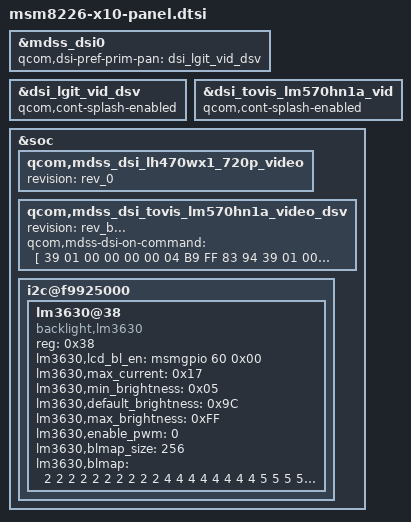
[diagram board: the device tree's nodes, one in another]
/* Copyright (c) 2013, Code Aurora Forum. All rights reserved.
 *
 * This program is free software; you can redistribute it and/or modify
 * it under the terms of the GNU General Public License version 2 and
 * only version 2 as published by the Free Software Foundation.
 *
 * This program is distributed in the hope that it will be useful,
 * but WITHOUT ANY WARRANTY; without even the implied warranty of
 * MERCHANTABILITY or FITNESS FOR A PARTICULAR PURPOSE.  See the
 * GNU General Public License for more details.
 */

&mdss_dsi0 {
	qcom,dsi-pref-prim-pan = <&dsi_lgit_vid_dsv>;
};

&dsi_lgit_vid_dsv {
	qcom,cont-splash-enabled;
};
&dsi_tovis_lm570hn1a_vid {
	qcom,cont-splash-enabled;
};

&soc {
	qcom,mdss_dsi_lh470wx1_720p_video {
		status = "ok";
		revision = "rev_0";
	};
	qcom,mdss_dsi_tovis_lm570hn1a_video_dsv {
		status = "ok";
		revision = "rev_a";
		qcom,mdss-dsi-on-command = [
		39 01 00 00 00 00 04	/*Set EXTC*/
		B9 FF 83 94

		39 01 00 00 00 00 03   /*Set MIPI*/
		BA 33 83

		39 01 00 00 00 00 10  /*Set Power*/
		B1 6C 12/*4 Power Mode*/ 12
		34 04 11 F1
		80 FF 54 23
		80 C0 D2 58

		39 01 00 00 00 00 0C /*Set Display*/
		B2 00 64 0E
		0D 32 1C 08
		08 1C 4D 00

		39 01 00 00 00 00 0D /*Set CYC*/
		B4 00 FF 51
		5A 59 5A 03
		5A 01 70 01
		70

		/*Set VCOM*/
		39 01 00 00 00 00 04
		B6 73 73 E0

		/*Set Gamma*/
		39 01 00 00 00 00 2B
		E0 00 29 2C 2F 31 3F 2A 3F 06 0A 0C 17 0E 11 14 12 14 08 12 12
		16 00 29 2B 2D 32 3F 2A 3F 08 0B 0C 17 0D 10 13 12 12 06 11 13 18

		39 01 00 00 00 00 26 /*Set GIP*/
		D3 00 07 00
		40 07 10 00
		08 10 08 00
		08 54 15 0E
		05 0E 02 15
		06 05 06 47
		44 0A 0A 4B
		10 07 07 08
		00 00 00 0A
		00 01

		39 01 00 00 00 00 2D /*GIP Forward*/
		D5 1A 1A 1B
		1B 00 01 02
		03 04 05 06
		07 08 09 0A
		0B 24 25 18
		18 26 27 18
		18 18 18 18
		18 18 18 18
		18 18 18 18
		18 18 18 20
		21 18 18 18
		18

		39 01 00 00 00 00 2D /*GIP Backward*/
		D6 1A 1A 1B
		1B 0B 0A 09
		08 07 06 05
		04 03 02 01
		00 21 20 58
		58 27 26 18
		18 18 18 18
		18 18 18 18
		18 18 18 18
		18 18 18 25
		24 18 18 18
		18

		39 01 00 00 00 00 02  /*Set Panel*/
		CC 09

		39 01 00 00 00 00 05  /*Set TCON*/
		C7 00 C0 00
		C0

		/*05 01 00 00 78 00 01	  11  */  /*Sleep out*/

		/* set_chemode */
		39 01 00 00 00 00 03
		E4 01 00

		/* set_che */
		39 01 00 00 00 00 13
		E5 00 0C 1F
		07 04 00 08
		20 00 10 00
		00 08 06 04
		00 80 0E

		/* set_chesel */
		39 01 00 00 00 00 12
		E6 40 00 00
		05 05 10 10
		10 04 04 08
		10 10 10 10
		1010

		/*05 01 00 00 0A 00 01	  29 */  /*Display on*/


		/* CABC */
		/*
		15 01 00 00 00 00 02 51 FF
		15 01 00 00 00 00 02 53 24
		15 01 00 00 05 00 02 55 01
		39 01 00 00 00 00 0A
		C9 0F 00 1E 02 00 80 00 01 3E
		*/
		/* CABC */
		/*
		05 01 00 00 96 00 02 11 00
		39 01 00 00 00 00 14
		B1 00 00 07 E3 91 10 11 6F 0C 1D 25 1E 1E 41 01 58 F7 00 00
		05 01 00 00 0a 00 01 29 */
		];
	};

	qcom,mdss_dsi_tovis_lm570hn1a_video_dsv {
		status = "ok";
		revision = "rev_b...";
		qcom,mdss-dsi-on-command = [
		39 01 00 00 00 00 04	/*Set EXTC*/
		B9 FF 83 94

		39 01 00 00 00 00 03   /*Set MIPI*/
		BA 33 83

		39 01 00 00 00 00 10  /*Set Power*/
		B1 6C 52/*3 Power Mode*/ 12
		34 04 11 F1
		80 FF 54 23
		80 C0 D2 58

		39 01 00 00 00 00 0C /*Set Display*/
		B2 00 64 0E
		0D 32 1C 08
		08 1C 4D 00

		39 01 00 00 00 00 0D /*Set CYC*/
		B4 00 FF 51
		5A 59 5A 03
		5A 01 70 01
		70

		/*Set VCOM*/
		39 01 00 00 00 00 04
		B6 73 73 E0

		/*Set Gamma*/
		39 01 00 00 00 00 2B
		E0 00 29 2C 2F 31 3F 2A 3F 06 0A 0C 17 0E 11 14 12 14 08 12 12
		16 00 29 2B 2D 32 3F 2A 3F 08 0B 0C 17 0D 10 13 12 12 06 11 13 18

		39 01 00 00 00 00 26 /*Set GIP*/
		D3 00 07 00
		40 07 10 00
		08 10 08 00
		08 54 15 0E
		05 0E 02 15
		06 05 06 47
		44 0A 0A 4B
		10 07 07 08
		00 00 00 0A
		00 01

		39 01 00 00 00 00 2D /*GIP Forward*/
		D5 1A 1A 1B
		1B 00 01 02
		03 04 05 06
		07 08 09 0A
		0B 24 25 18
		18 26 27 18
		18 18 18 18
		18 18 18 18
		18 18 18 18
		18 18 18 20
		21 18 18 18
		18

		39 01 00 00 00 00 2D /*GIP Backward*/
		D6 1A 1A 1B
		1B 0B 0A 09
		08 07 06 05
		04 03 02 01
		00 21 20 58
		58 27 26 18
		18 18 18 18
		18 18 18 18
		18 18 18 18
		18 18 18 25
		24 18 18 18
		18

		39 01 00 00 00 00 02  /*Set Panel*/
		CC 09

		39 01 00 00 00 00 05  /*Set TCON*/
		C7 00 C0 00
		C0

		/*05 01 00 00 78 00 01	  11  */  /*Sleep out*/

		/* set_chemode */
		39 01 00 00 00 00 03
		E4 01 00

		/* set_che */
		39 01 00 00 00 00 13
		E5 00 0C 1F
		07 04 00 08
		20 00 10 00
		00 08 06 04
		00 80 0E

		/* set_chesel */
		39 01 00 00 00 00 12
		E6 40 00 00
		05 05 10 10
		10 04 04 08
		10 10 10 10
		1010

		/*05 01 00 00 0A 00 01	  29 */  /*Display on*/


		/* CABC */
		/*
		15 01 00 00 00 00 02 51 FF
		15 01 00 00 00 00 02 53 24
		15 01 00 00 05 00 02 55 01
		39 01 00 00 00 00 0A
		C9 0F 00 1E 02 00 80 00 01 3E
		*/
		/* CABC */
		/*
		05 01 00 00 96 00 02 11 00
		39 01 00 00 00 00 14
		B1 00 00 07 E3 91 10 11 6F 0C 1D 25 1E 1E 41 01 58 F7 00 00
		05 01 00 00 0a 00 01 29 */
		];
	};


	i2c@f9925000 { /* BLSP1 QUP3 */
		lm3630@38 {
			compatible = "backlight,lm3630";
			status = "ok";
			reg = <0x38>;
			lm3630,lcd_bl_en = <&msmgpio 60 0x00>;
			lm3630,max_current = <0x17>;
			lm3630,min_brightness = <0x05>;
			lm3630,default_brightness = <0x9C>;
			lm3630,max_brightness = <0xFF>;
			lm3630,enable_pwm = <0>;
			lm3630,blmap_size = <256>;
			lm3630,blmap = <
				2 2 2 2 2 2 2 2 2 2
				/*0% (10th)*/
				4 4 4 4 4	4 4 4 5 5
				5 5 5 5 5 5 6 6 6 6
				6 6 6 6 7 7 7 7 7 7
				7 7 8 8 8	8 8 8 9 9
				9 9 9 9 9 9 10 10 10 10
				/*20%(60th) */
				10 10 10 10 11 11 11 12 12 12
				13 13 13 14 14 14 15 15 16 16
				17 17 18 18 19 19 20 20 21 21
				22 22 23	23 24 24 25 25 26 26
				27 27 27	28 28 28 29 29
				/*40%(108th)*/
				29 29
				29 29 29 29 32 32 32 33 34 35
				37 38 39 40 41 41 42 43 46 46
				46 48 51 52 53 54 50 50 51 52
				53 53 54 55 55 56 57 57 58 59
				59 60 61 62 64 64 64 64 64
				/*60% (159th)*/
				64 64 64 65 66 67 67 67 67 69 71
				73 74 75 76 77 78 79 80 81 82
				83 84 85 86 87 88 89 90 91 92
				94 96 98 100 102 104 106 108 110 112
				114 116 117 118 119 120 120
				/*80% (207th)*/
				120 120 120
				120 124 126 128 131 134 137 139 140 142
				144 146 148 150 152 154 156 158 159 160
				162 164 166 167 169 171 173 175 177 178
				180 181 183 185 186 187 188 190 192 193
				195 197 196 198 200 200>;
		};
	};
};
